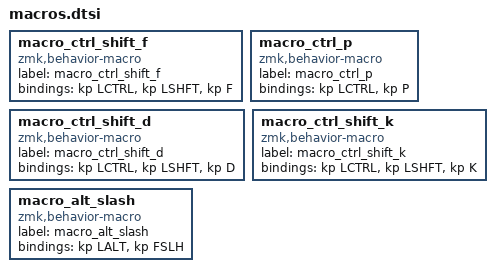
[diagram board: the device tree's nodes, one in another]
macro_ctrl_shift_f: macro_ctrl_shift_f{
compatible = "zmk,behavior-macro";
label = "macro_ctrl_shift_f";
#binding-cells = <0>;
bindings = <&kp LCTRL>, <&kp LSHFT>, <&kp F>;
};
macro_ctrl_p: macro_ctrl_p{
compatible = "zmk,behavior-macro";
label = "macro_ctrl_p";
#binding-cells = <0>;
bindings = <&kp LCTRL>, <&kp P>;
};
macro_ctrl_shift_d: macro_ctrl_shift_d{
compatible = "zmk,behavior-macro";
label = "macro_ctrl_shift_d";
#binding-cells = <0>;
bindings = <&kp LCTRL>, <&kp LSHFT>, <&kp D>;
};
macro_ctrl_shift_k: macro_ctrl_shift_k{
compatible = "zmk,behavior-macro";
label = "macro_ctrl_shift_k";
#binding-cells = <0>;
bindings = <&kp LCTRL>, <&kp LSHFT>, <&kp K>;
};
macro_alt_slash: macro_alt_slash{
compatible = "zmk,behavior-macro";
label = "macro_alt_slash";
#binding-cells = <0>;
bindings = <&kp LALT>, <&kp FSLH>;
};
